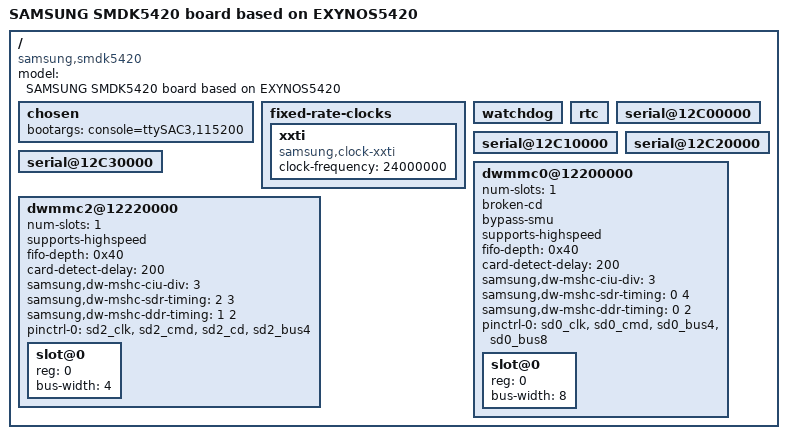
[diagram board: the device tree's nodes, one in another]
/*
 * SAMSUNG SMDK5420 board device tree source
 *
 * Copyright (c) 2013 Samsung Electronics Co., Ltd.
 *		http://www.samsung.com
 *
 * This program is free software; you can redistribute it and/or modify
 * it under the terms of the GNU General Public License version 2 as
 * published by the Free Software Foundation.
*/

/dts-v1/;
/include/ "exynos5420.dtsi"

/ {
	model = "SAMSUNG SMDK5420 board based on EXYNOS5420";
	compatible = "samsung,smdk5420", "samsung,exynos5420";

	chosen {
		bootargs = "console=ttySAC3,115200";
	};

	fixed-rate-clocks {
		xxti {
			compatible = "samsung,clock-xxti";
			clock-frequency = <24000000>;
		};
	};

	watchdog {
		status = "okay";
	};

	rtc {
		status = "okay";
	};

	serial@12C00000 {
		status = "okay";
	};

	serial@12C10000 {
		status = "okay";
	};

	serial@12C20000 {
		status = "okay";
	};

	serial@12C30000 {
		status = "okay";
	};

	dwmmc0@12200000 {
		status = "okay";
		num-slots = <1>;
		broken-cd;
		bypass-smu;
		supports-highspeed;
		fifo-depth = <0x40>;
		card-detect-delay = <200>;
		samsung,dw-mshc-ciu-div = <3>;
		samsung,dw-mshc-sdr-timing = <0 4>;
		samsung,dw-mshc-ddr-timing = <0 2>;
		pinctrl-names = "default";
		pinctrl-0 = <&sd0_clk &sd0_cmd &sd0_bus4 &sd0_bus8>;

		slot@0 {
			reg = <0>;
			bus-width = <8>;
		};
	};

	dwmmc2@12220000 {
		status = "okay";
		num-slots = <1>;
		supports-highspeed;
		fifo-depth = <0x40>;
		card-detect-delay = <200>;
		samsung,dw-mshc-ciu-div = <3>;
		samsung,dw-mshc-sdr-timing = <2 3>;
		samsung,dw-mshc-ddr-timing = <1 2>;
		pinctrl-names = "default";
		pinctrl-0 = <&sd2_clk &sd2_cmd &sd2_cd &sd2_bus4>;

		slot@0 {
			reg = <0>;
			bus-width = <4>;
		};
	};
};
